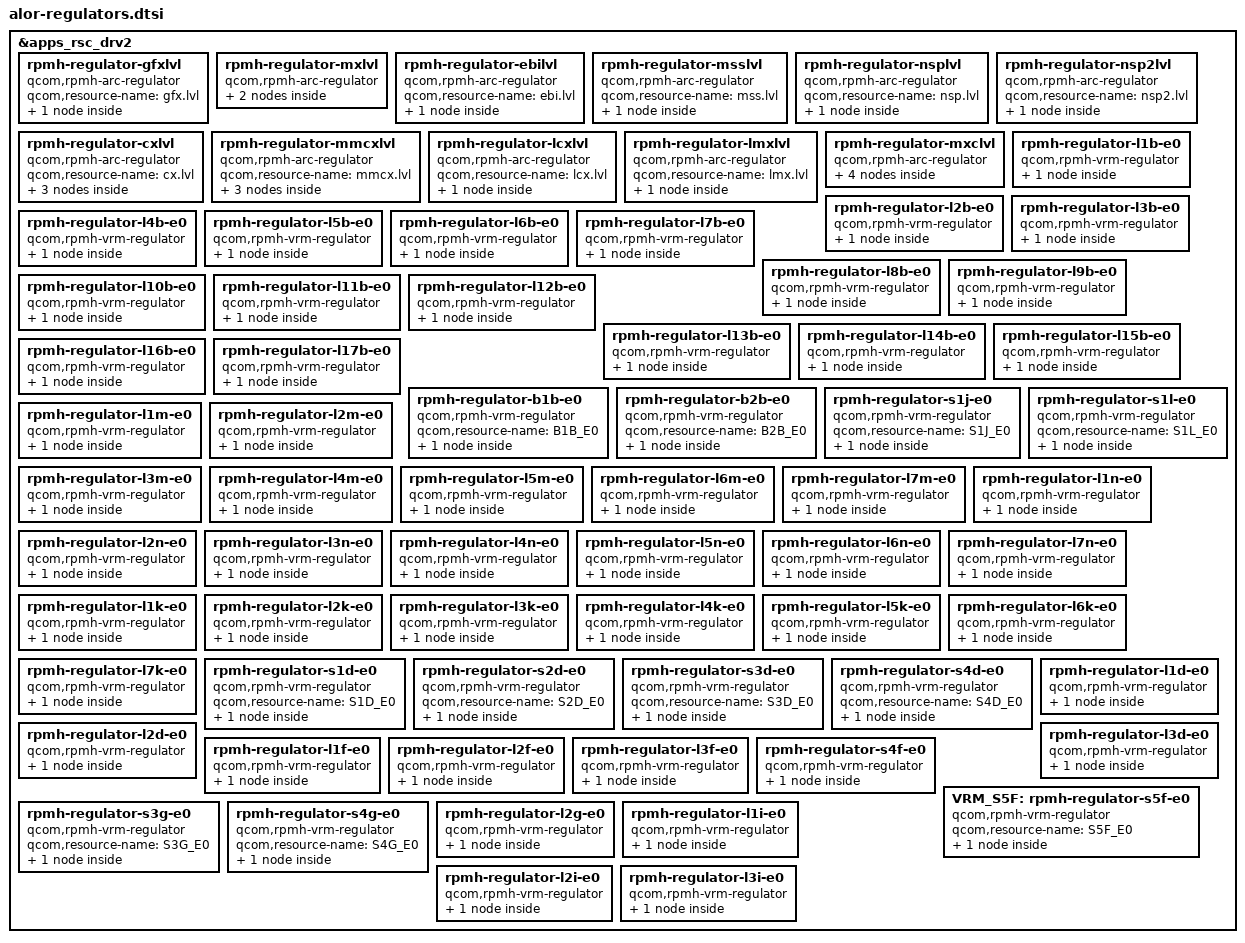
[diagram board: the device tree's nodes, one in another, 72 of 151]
// SPDX-License-Identifier: BSD-3-Clause
/*
 * Copyright (c) Qualcomm Technologies, Inc. and/or its subsidiaries.
 */

#include <dt-bindings/regulator/qcom,rpmh-regulator-levels.h>

&apps_rsc_drv2 {
	rpmh-regulator-gfxlvl {
		compatible = "qcom,rpmh-arc-regulator";
		qcom,resource-name = "gfx.lvl";
		VDD_GFX_LEVEL:
		S6G_LEVEL: S6G_E0_LEVEL:
		pm8550ve_g_s6_level: vreg-pm8550ve-g-s6-level {
			regulator-name = "pm8550ve_g_s6_level";
			qcom,set = <RPMH_REGULATOR_SET_ALL>;
			regulator-min-microvolt =
				<RPMH_REGULATOR_LEVEL_RETENTION>;
			regulator-max-microvolt =
				<RPMH_REGULATOR_LEVEL_MAX>;
			qcom,init-voltage-level =
				<RPMH_REGULATOR_LEVEL_RETENTION>;
		};
	};

	rpmh-regulator-mxlvl {
		compatible = "qcom,rpmh-arc-regulator";
		qcom,resource-name = "mx.lvl";
		proxy-supply = <&VDD_MXA_LEVEL>;
		VDD_MXA_LEVEL: VDD_MX_LEVEL:
		S8F_LEVEL: S8F_E0_LEVEL:
		pm8550ve_f_s8_level: vreg-pm8550ve-f-s8-level {
			regulator-name = "pm8550ve_f_s8_level";
			qcom,set = <RPMH_REGULATOR_SET_ALL>;
			regulator-min-microvolt =
				<RPMH_REGULATOR_LEVEL_RETENTION>;
			regulator-max-microvolt =
				<RPMH_REGULATOR_LEVEL_MAX>;
			qcom,init-voltage-level =
				<RPMH_REGULATOR_LEVEL_TURBO>;
			qcom,proxy-consumer-enable;
			qcom,proxy-consumer-voltage =
				<RPMH_REGULATOR_LEVEL_TURBO
				 RPMH_REGULATOR_LEVEL_MAX>;
		};

		VDD_MXA_LEVEL_AO: VDD_MX_LEVEL_AO:
		S8F_LEVEL_AO: S8F_E0_LEVEL_A0:
		pm8550ve_f_s8_level_ao: vreg-pm8550ve-f-s8-level-ao {
			regulator-name = "pm8550ve_f_s8_level_ao";
			qcom,set = <RPMH_REGULATOR_SET_ACTIVE>;
			regulator-min-microvolt =
				<RPMH_REGULATOR_LEVEL_RETENTION>;
			regulator-max-microvolt =
				<RPMH_REGULATOR_LEVEL_MAX>;
			qcom,init-voltage-level =
				<RPMH_REGULATOR_LEVEL_RETENTION>;
		};
	};

	rpmh-regulator-ebilvl {
		compatible = "qcom,rpmh-arc-regulator";
		qcom,resource-name = "ebi.lvl";
		VDD_EBI_LEVEL:
		S1C_LEVEL: S1C_E0_LEVEL:
		pmg1110_c_s1_level: vreg-pmg1110-c-s1-level {
			regulator-name = "pmg1110_c_s1_level";
			qcom,set = <RPMH_REGULATOR_SET_ALL>;
			regulator-min-microvolt =
				<RPMH_REGULATOR_LEVEL_RETENTION>;
			regulator-max-microvolt =
				<RPMH_REGULATOR_LEVEL_MAX>;
			qcom,init-voltage-level =
				<RPMH_REGULATOR_LEVEL_RETENTION>;
		};
	};

	rpmh-regulator-msslvl {
		compatible = "qcom,rpmh-arc-regulator";
		qcom,resource-name = "mss.lvl";
		VDD_MODEM_LEVEL:
		S5G_LEVEL: S5G_E0_LEVEL:
		pm8550ve_g_s5_level: vreg-pm8550ve-g-s5-level {
			regulator-name = "pm8550ve_g_s5_level";
			qcom,set = <RPMH_REGULATOR_SET_ALL>;
			regulator-min-microvolt =
				<RPMH_REGULATOR_LEVEL_RETENTION>;
			regulator-max-microvolt =
				<RPMH_REGULATOR_LEVEL_MAX>;
			qcom,init-voltage-level =
				<RPMH_REGULATOR_LEVEL_RETENTION>;
		};
	};

	rpmh-regulator-nsplvl {
		compatible = "qcom,rpmh-arc-regulator";
		qcom,resource-name = "nsp.lvl";
		VDD_NSP1_LEVEL:
		S5D_LEVEL: S5D_E0_LEVEL:
		pm8550ve_d_s5_level: vreg-pm8550ve-d-s5-level {
			regulator-name = "pm8550ve_d_s5_level";
			qcom,set = <RPMH_REGULATOR_SET_ALL>;
			regulator-min-microvolt =
				<RPMH_REGULATOR_LEVEL_RETENTION>;
			regulator-max-microvolt =
				<RPMH_REGULATOR_LEVEL_MAX>;
			qcom,init-voltage-level =
				<RPMH_REGULATOR_LEVEL_RETENTION>;
		};
	};

	rpmh-regulator-nsp2lvl {
		compatible = "qcom,rpmh-arc-regulator";
		qcom,resource-name = "nsp2.lvl";
		VDD_NSP2_LEVEL:
		S7D_LEVEL: S7D_E0_LEVEL:
		pm8550ve_d_s7_level: vreg-pm850ve-d-s7-level {
			regulator-name = "pm8550ve_d_s7_level";
			qcom,set = <RPMH_REGULATOR_SET_ALL>;
			regulator-min-microvolt =
				<RPMH_REGULATOR_LEVEL_RETENTION>;
			regulator-max-microvolt =
				<RPMH_REGULATOR_LEVEL_MAX>;
			qcom,init-voltage-level =
				<RPMH_REGULATOR_LEVEL_RETENTION>;
		};
	};

	rpmh-regulator-cxlvl {
		compatible = "qcom,rpmh-arc-regulator";
		qcom,resource-name = "cx.lvl";
		VDD_CX_LEVEL:
		S1F_LEVEL: S1F_E0_LEVEL:
		pm8550ve_f_s1_level: vreg-pm8550ve-f-s1-level {
			regulator-name = "pm8550ve_f_s1_level";
			qcom,set = <RPMH_REGULATOR_SET_ALL>;
			regulator-min-microvolt =
				<RPMH_REGULATOR_LEVEL_RETENTION>;
			regulator-max-microvolt =
				<RPMH_REGULATOR_LEVEL_MAX>;
			qcom,init-voltage-level =
				<RPMH_REGULATOR_LEVEL_TURBO>;
		};

		VDD_CX_LEVEL_AO:
		S1F_LEVEL_AO: S1F_E0_LEVEL_A0:
		pm8550ve_f_s1_level_ao: vreg-pm8550ve0-f-s1-level-ao {
			regulator-name = "pm8550ve_f_s1_level_ao";
			qcom,set = <RPMH_REGULATOR_SET_ACTIVE>;
			regulator-min-microvolt =
				<RPMH_REGULATOR_LEVEL_RETENTION>;
			regulator-max-microvolt =
				<RPMH_REGULATOR_LEVEL_MAX>;
			qcom,init-voltage-level =
				<RPMH_REGULATOR_LEVEL_RETENTION>;
		};

		VDD_CX_MMCX_SUPPLY_LEVEL:
		vreg-pm8550ve-f-s1-mmcx-sup-level {
			regulator-name = "pm8550ve_f_s1_mmcx_sup_level";
			qcom,set = <RPMH_REGULATOR_SET_ALL>;
			regulator-min-microvolt =
				<RPMH_REGULATOR_LEVEL_MIN_SVS>;
			regulator-max-microvolt =
				<RPMH_REGULATOR_LEVEL_MAX>;
			qcom,init-voltage-level =
				<RPMH_REGULATOR_LEVEL_MIN_SVS>;
		};
	};

	rpmh-regulator-mmcxlvl {
		compatible = "qcom,rpmh-arc-regulator";
		qcom,resource-name = "mmcx.lvl";
		VDD_MMCX_LEVEL: VDD_MM_LEVEL:
		S2F_LEVEL: S2F_E0_LEVEL:
		pm8550ve_f_s2_level: vreg-pm8550ve-f-s2-level {
			regulator-name = "pm8550ve_f_s2_level";
			qcom,set = <RPMH_REGULATOR_SET_ALL>;
			pm8550ve_f_s2_level-parent-supply =
				<&VDD_CX_MMCX_SUPPLY_LEVEL>;
			regulator-min-microvolt =
				<RPMH_REGULATOR_LEVEL_LOW_SVS_D1>;
			regulator-max-microvolt =
				<RPMH_REGULATOR_LEVEL_MAX>;
			qcom,init-voltage-level =
				<RPMH_REGULATOR_LEVEL_TURBO>;
		};

		VDD_MMCX_LEVEL_AO: VDD_MM_LEVEL_AO:
		S2F_LEVEL_AO: S2F_E0_LEVEL_A0:
		pm8550ve_f_s2_level_ao: vreg-pm8550ve-f-s2-level-ao {
			regulator-name = "pm8550ve_f_s2_level_ao";
			qcom,set = <RPMH_REGULATOR_SET_ACTIVE>;
			regulator-min-microvolt =
				<RPMH_REGULATOR_LEVEL_LOW_SVS_D1>;
			regulator-max-microvolt =
				<RPMH_REGULATOR_LEVEL_MAX>;
			qcom,init-voltage-level =
				<RPMH_REGULATOR_LEVEL_LOW_SVS_D1>;
		};

		vreg-pm8550ve-f-s2-level-so {
			regulator-name = "pm8550ve_f_s2_level_so";
			qcom,set = <RPMH_REGULATOR_SET_SLEEP>;
			regulator-min-microvolt =
				<RPMH_REGULATOR_LEVEL_LOW_SVS_D1>;
			regulator-max-microvolt =
				<RPMH_REGULATOR_LEVEL_MAX>;
			qcom,init-voltage-level =
				<RPMH_REGULATOR_LEVEL_LOW_SVS_D1>;
		};
	};

	rpmh-regulator-lcxlvl {
		compatible = "qcom,rpmh-arc-regulator";
		qcom,resource-name = "lcx.lvl";
		VDD_LPI_CX_LEVEL:
		L3G_LEVEL: L3G_E0_LEVEL:
		pm8550ve_g_l3_level: vreg-pm8550ve-g-l3-level {
			regulator-name = "pm8550ve_g_l3_level";
			qcom,set = <RPMH_REGULATOR_SET_ALL>;
			regulator-min-microvolt =
				<RPMH_REGULATOR_LEVEL_RETENTION>;
			regulator-max-microvolt =
				<RPMH_REGULATOR_LEVEL_MAX>;
			qcom,init-voltage-level =
				<RPMH_REGULATOR_LEVEL_RETENTION>;
		};
	};

	rpmh-regulator-lmxlvl {
		compatible = "qcom,rpmh-arc-regulator";
		qcom,resource-name = "lmx.lvl";
		VDD_LPI_MX_LEVEL:
		L1G_LEVEL: L1G_E0_LEVEL:
		pm8550ve_g_l1_level: vreg-pm8550ve-g-l1-level {
			regulator-name = "pm8550ve_g_l1_level";
			qcom,set = <RPMH_REGULATOR_SET_ALL>;
			regulator-min-microvolt =
				<RPMH_REGULATOR_LEVEL_RETENTION>;
			regulator-max-microvolt =
				<RPMH_REGULATOR_LEVEL_MAX>;
			qcom,init-voltage-level =
				<RPMH_REGULATOR_LEVEL_RETENTION>;
		};
	};

	rpmh-regulator-mxclvl {
		compatible = "qcom,rpmh-arc-regulator";
		qcom,resource-name = "mxc.lvl";
		proxy-supply = <&VDD_MXC_LEVEL>;
		VDD_MXC_LEVEL:
		S1G_LEVEL: S1G_E0_LEVEL:
		pm8550ve_g_s1_level: vreg-pm8550ve-g-s1-level {
			regulator-name = "pm8550ve_g_s1_level";
			qcom,set = <RPMH_REGULATOR_SET_ALL>;
			regulator-min-microvolt =
				<RPMH_REGULATOR_LEVEL_RETENTION>;
			regulator-max-microvolt =
				<RPMH_REGULATOR_LEVEL_MAX>;
			qcom,init-voltage-level =
				<RPMH_REGULATOR_LEVEL_TURBO>;
			qcom,proxy-consumer-enable;
			qcom,proxy-consumer-voltage =
				<RPMH_REGULATOR_LEVEL_TURBO
				 RPMH_REGULATOR_LEVEL_MAX>;
		};

		VDD_MXC_LEVEL_AO:
		S1G_LEVEL_AO: S1G_E0_LEVEL_A0:
		pm8550ve_g_s1_level_ao: vreg-pm8550ve-g-s1-level-ao {
			regulator-name = "pm8550ve_g_s1_level_ao";
			qcom,set = <RPMH_REGULATOR_SET_ACTIVE>;
			regulator-min-microvolt =
				<RPMH_REGULATOR_LEVEL_RETENTION>;
			regulator-max-microvolt =
				<RPMH_REGULATOR_LEVEL_MAX>;
			qcom,init-voltage-level =
				<RPMH_REGULATOR_LEVEL_RETENTION>;
		};

		VDD_MXC_MMCX_VOTER_LEVEL: VDD_MXC_MM_VOTER_LEVEL:
		VDD_MM_MXC_VOTER_LEVEL: vreg-pm8550ve-g-s1-mmcx-voter-level {
			regulator-name = "pm8550ve_g_s1_mmcx_voter_level";
			pm8550ve_g_s1_mmcx_voter_level-parent-supply =
				<&VDD_MMCX_LEVEL>;
			qcom,set = <RPMH_REGULATOR_SET_ALL>;
			regulator-min-microvolt =
				<RPMH_REGULATOR_LEVEL_MIN_SVS>;
			regulator-max-microvolt =
				<RPMH_REGULATOR_LEVEL_MAX>;
			qcom,init-voltage-level =
				<RPMH_REGULATOR_LEVEL_MIN_SVS>;
		};

		VDD_MXC_GFX_VOTER_LEVEL: VDD_GFX_MXC_VOTER_LEVEL:
			vreg-pm8550ve-g-s1-gfx-voter-level {
			regulator-name = "pm8550ve_g_s1_gfx_voter_level";
			pm8550ve_g_s1_gfx_voter_level-parent-supply =
				<&VDD_GFX_LEVEL>;
			qcom,set = <RPMH_REGULATOR_SET_ALL>;
			regulator-min-microvolt =
				<RPMH_REGULATOR_LEVEL_MIN_SVS>;
			regulator-max-microvolt =
				<RPMH_REGULATOR_LEVEL_MAX>;
			qcom,init-voltage-level =
				<RPMH_REGULATOR_LEVEL_MIN_SVS>;
		};
	};

	rpmh-regulator-l1b-e0 {
		compatible = "qcom,rpmh-vrm-regulator";
		qcom,resource-name = "L1B_E0";
		qcom,regulator-type = "pmic5-ldo";
		qcom,supported-modes =
			<RPMH_REGULATOR_MODE_LPM
			 RPMH_REGULATOR_MODE_HPM>;
		qcom,mode-threshold-currents = <0 30000>;

		L1B: L1B_E0: pm_humu_l1: vreg-pm-humu-l1 {
			regulator-name = "pm_humu_l1";
			qcom,set = <RPMH_REGULATOR_SET_ALL>;
			regulator-min-microvolt = <1080000>;
			regulator-max-microvolt = <2000000>;
			qcom,init-voltage = <1080000>;
			qcom,init-mode = <RPMH_REGULATOR_MODE_HPM>;
		};
	};

	rpmh-regulator-l2b-e0 {
		compatible = "qcom,rpmh-vrm-regulator";
		qcom,resource-name = "L2B_E0";
		qcom,regulator-type = "pmic5-ldo";
		qcom,supported-modes =
			<RPMH_REGULATOR_MODE_LPM
			 RPMH_REGULATOR_MODE_HPM>;
		qcom,mode-threshold-currents = <0 10000>;

		L2B: L2B_E0: pm_humu_l2: vreg-pm-humu-l2 {
			regulator-name = "pm_humu_l2";
			qcom,set = <RPMH_REGULATOR_SET_ALL>;
			regulator-min-microvolt = <2600000>;
			regulator-max-microvolt = <3544000>;
			qcom,init-voltage = <2600000>;
			qcom,init-mode = <RPMH_REGULATOR_MODE_HPM>;
		};
	};

	rpmh-regulator-l3b-e0 {
		compatible = "qcom,rpmh-vrm-regulator";
		qcom,resource-name = "L3B_E0";
		qcom,regulator-type = "pmic5-ldo";
		qcom,supported-modes =
			<RPMH_REGULATOR_MODE_LPM
			 RPMH_REGULATOR_MODE_HPM>;
		qcom,mode-threshold-currents = <0 10000>;

		L3B: L3B_E0: pm_humu_l3: vreg-pm-humu-l3 {
			regulator-name = "pm_humu_l3";
			qcom,set = <RPMH_REGULATOR_SET_ALL>;
			regulator-min-microvolt = <1170000>;
			regulator-max-microvolt = <1370000>;
			qcom,init-voltage = <1200000>;
			qcom,init-mode = <RPMH_REGULATOR_MODE_HPM>;
		};
	};

	rpmh-regulator-l4b-e0 {
		compatible = "qcom,rpmh-vrm-regulator";
		qcom,resource-name = "L4B_E0";
		qcom,regulator-type = "pmic5-ldo";
		qcom,supported-modes =
			<RPMH_REGULATOR_MODE_LPM
			 RPMH_REGULATOR_MODE_HPM>;
		qcom,mode-threshold-currents = <0 30000>;

		L4B: L4B_E0: pm_humu_l4: vreg-pm-humu-l4 {
			regulator-name = "pm_humu_l4";
			qcom,set = <RPMH_REGULATOR_SET_ALL>;
			regulator-min-microvolt = <1650000>;
			regulator-max-microvolt = <1950000>;
			qcom,init-voltage = <1650000>;
			qcom,init-mode = <RPMH_REGULATOR_MODE_HPM>;
		};
	};

	rpmh-regulator-l5b-e0 {
		compatible = "qcom,rpmh-vrm-regulator";
		qcom,resource-name = "L5B_E0";
		qcom,regulator-type = "pmic5-ldo";
		qcom,supported-modes =
			<RPMH_REGULATOR_MODE_LPM
			 RPMH_REGULATOR_MODE_HPM>;
		qcom,mode-threshold-currents = <0 10000>;

		L5B: L5B_E0: pm_humu_l5: vreg-pm-humu-l5 {
			regulator-name = "pm_humu_l5";
			qcom,set = <RPMH_REGULATOR_SET_ALL>;
			regulator-min-microvolt = <2700000>;
			regulator-max-microvolt = <3554000>;
			qcom,init-voltage = <3104000>;
			qcom,init-mode = <RPMH_REGULATOR_MODE_HPM>;
		};
	};

	rpmh-regulator-l6b-e0 {
		compatible = "qcom,rpmh-vrm-regulator";
		qcom,resource-name = "L6B_E0";
		qcom,regulator-type = "pmic5-ldo";
		qcom,supported-modes =
			<RPMH_REGULATOR_MODE_LPM
			 RPMH_REGULATOR_MODE_HPM>;
		qcom,mode-threshold-currents = <0 10000>;

		L6B: L6B_E0: pm_humu_l6: vreg-pm-humu-l6 {
			regulator-name = "pm_humu_l6";
			qcom,set = <RPMH_REGULATOR_SET_ALL>;
			regulator-min-microvolt = <1504000>;
			regulator-max-microvolt = <3544000>;
			qcom,init-voltage = <1504000>;
			qcom,init-mode = <RPMH_REGULATOR_MODE_HPM>;
		};
	};

	rpmh-regulator-l7b-e0 {
		compatible = "qcom,rpmh-vrm-regulator";
		qcom,resource-name = "L7B_E0";
		qcom,regulator-type = "pmic5-ldo";
		qcom,supported-modes =
			<RPMH_REGULATOR_MODE_LPM
			 RPMH_REGULATOR_MODE_HPM>;
		qcom,mode-threshold-currents = <0 10000>;

		L7B: L7B_E0: pm_humu_l7: vreg-pm-humu-l7 {
			regulator-name = "pm_humu_l7";
			qcom,set = <RPMH_REGULATOR_SET_ALL>;
			regulator-min-microvolt = <1504000>;
			regulator-max-microvolt = <3544000>;
			qcom,init-voltage = <1504000>;
			qcom,init-mode = <RPMH_REGULATOR_MODE_HPM>;
		};
	};

	rpmh-regulator-l8b-e0 {
		compatible = "qcom,rpmh-vrm-regulator";
		qcom,resource-name = "L8B_E0";
		qcom,regulator-type = "pmic5-ldo";
		qcom,supported-modes =
			<RPMH_REGULATOR_MODE_LPM
			 RPMH_REGULATOR_MODE_HPM>;
		qcom,mode-threshold-currents = <0 10000>;

		L8B: L8B_E0: pm_humu_l8: vreg-pm-humu-l8 {
			regulator-name = "pm_humu_l8";
			qcom,set = <RPMH_REGULATOR_SET_ALL>;
			regulator-min-microvolt = <1650000>;
			regulator-max-microvolt = <3544000>;
			qcom,init-voltage = <1650000>;
			qcom,init-mode = <RPMH_REGULATOR_MODE_HPM>;
		};
	};

	rpmh-regulator-l9b-e0 {
		compatible = "qcom,rpmh-vrm-regulator";
		qcom,resource-name = "L9B_E0";
		qcom,regulator-type = "pmic5-ldo";
		qcom,supported-modes =
			<RPMH_REGULATOR_MODE_LPM
			 RPMH_REGULATOR_MODE_HPM>;
		qcom,mode-threshold-currents = <0 10000>;

		L9B: L9B_E0: pm_humu_l9: vreg-pm-humu-l9 {
			regulator-name = "pm_humu_l9";
			qcom,set = <RPMH_REGULATOR_SET_ALL>;
			regulator-min-microvolt = <2700000>;
			regulator-max-microvolt = <3300000>;
			qcom,init-voltage = <2700000>;
			qcom,init-mode = <RPMH_REGULATOR_MODE_HPM>;
		};
	};

	rpmh-regulator-l10b-e0 {
		compatible = "qcom,rpmh-vrm-regulator";
		qcom,resource-name = "L10B_E0";
		qcom,regulator-type = "pmic5-ldo";
		qcom,supported-modes =
			<RPMH_REGULATOR_MODE_LPM
			 RPMH_REGULATOR_MODE_HPM>;
		qcom,mode-threshold-currents = <0 30000>;
		proxy-supply = <&L10B>;

		L10B: L10B_E0: pm_humu_l10: vreg-pm-humu-l10 {
			regulator-name = "pm_humu_l10";
			qcom,set = <RPMH_REGULATOR_SET_ALL>;
			regulator-min-microvolt = <1650000>;
			regulator-max-microvolt = <1950000>;
			qcom,init-voltage = <1650000>;
			qcom,init-mode = <RPMH_REGULATOR_MODE_HPM>;
			qcom,proxy-consumer-enable;
			qcom,proxy-consumer-current = <154000>;
		};
	};

	rpmh-regulator-l11b-e0 {
		compatible = "qcom,rpmh-vrm-regulator";
		qcom,resource-name = "L11B_E0";
		qcom,regulator-type = "pmic5-ldo";
		qcom,supported-modes =
			<RPMH_REGULATOR_MODE_LPM
			 RPMH_REGULATOR_MODE_HPM>;
		qcom,mode-threshold-currents = <0 30000>;
		proxy-supply = <&L11B>;

		L11B: L11B_E0: pm_humu_l11: vreg-pm-humu-l11 {
			regulator-name = "pm_humu_l11";
			qcom,set = <RPMH_REGULATOR_SET_ALL>;
			regulator-min-microvolt = <1030000>;
			regulator-max-microvolt = <1100000>;
			qcom,init-voltage = <1030000>;
			qcom,init-mode = <RPMH_REGULATOR_MODE_HPM>;
			qcom,proxy-consumer-enable;
			qcom,proxy-consumer-current = <220000>;
		};
	};

	rpmh-regulator-l12b-e0 {
		compatible = "qcom,rpmh-vrm-regulator";
		qcom,resource-name = "L12B_E0";
		qcom,regulator-type = "pmic5-ldo";
		qcom,supported-modes =
			<RPMH_REGULATOR_MODE_LPM
			 RPMH_REGULATOR_MODE_HPM>;
		qcom,mode-threshold-currents = <0 30000>;

		L12B: L12B_E0: pm_humu_l12: vreg-pm-humu-l12 {
			regulator-name = "pm_humu_l12";
			qcom,set = <RPMH_REGULATOR_SET_ALL>;
			regulator-min-microvolt = <1080000>;
			regulator-max-microvolt = <1320000>;
			qcom,init-voltage = <1080000>;
			qcom,init-mode = <RPMH_REGULATOR_MODE_HPM>;
		};
	};

	rpmh-regulator-l13b-e0 {
		compatible = "qcom,rpmh-vrm-regulator";
		qcom,resource-name = "L13B_E0";
		qcom,regulator-type = "pmic5-ldo";
		qcom,supported-modes =
			<RPMH_REGULATOR_MODE_LPM
			 RPMH_REGULATOR_MODE_HPM>;
		qcom,mode-threshold-currents = <0 10000>;
		proxy-supply = <&L13B>;

		L13B: L13B_E0: pm_humu_l13: vreg-pm-humu-l13 {
			regulator-name = "pm_humu_l13";
			qcom,set = <RPMH_REGULATOR_SET_ALL>;
			regulator-min-microvolt = <2650000>;
			regulator-max-microvolt = <3544000>;
			qcom,init-voltage = <2650000>;
			qcom,init-mode = <RPMH_REGULATOR_MODE_HPM>;
			qcom,proxy-consumer-enable;
			qcom,proxy-consumer-current = <10000>;
		};
	};

	rpmh-regulator-l14b-e0 {
		compatible = "qcom,rpmh-vrm-regulator";
		qcom,resource-name = "L14B_E0";
		qcom,regulator-type = "pmic5-ldo";
		qcom,supported-modes =
			<RPMH_REGULATOR_MODE_LPM
			 RPMH_REGULATOR_MODE_HPM>;
		qcom,mode-threshold-currents = <0 10000>;

		L14B: L14B_E0: pm_humu_l14: vreg-pm-humu-l14 {
			regulator-name = "pm_humu_l14";
			qcom,set = <RPMH_REGULATOR_SET_ALL>;
			regulator-min-microvolt = <2700000>;
			regulator-max-microvolt = <3544000>;
			qcom,init-voltage = <2700000>;
			qcom,init-mode = <RPMH_REGULATOR_MODE_HPM>;
		};
	};

	rpmh-regulator-l15b-e0 {
		compatible = "qcom,rpmh-vrm-regulator";
		qcom,resource-name = "L15B_E0";
		qcom,regulator-type = "pmic5-ldo";
		qcom,supported-modes =
			<RPMH_REGULATOR_MODE_LPM
			 RPMH_REGULATOR_MODE_HPM>;
		qcom,mode-threshold-currents = <0 30000>;

		L15B: L15B_E0: pm_humu_l15: vreg-pm-humu-l15 {
			regulator-name = "pm_humu_l15";
			qcom,set = <RPMH_REGULATOR_SET_ALL>;
			regulator-min-microvolt = <1620000>;
			regulator-max-microvolt = <2000000>;
			qcom,init-voltage = <1800000>;
			qcom,init-mode = <RPMH_REGULATOR_MODE_HPM>;
		};
	};

	rpmh-regulator-l16b-e0 {
		compatible = "qcom,rpmh-vrm-regulator";
		qcom,resource-name = "L16B_E0";
		qcom,regulator-type = "pmic5-ldo";
		qcom,supported-modes =
			<RPMH_REGULATOR_MODE_LPM
			 RPMH_REGULATOR_MODE_HPM>;
		qcom,mode-threshold-currents = <0 10000>;

		L16B: L16B_E0: pm_humu_l16: vreg-pm-humu-l16 {
			regulator-name = "pm_humu_l16";
			qcom,set = <RPMH_REGULATOR_SET_ALL>;
			regulator-min-microvolt = <1600000>;
			regulator-max-microvolt = <3544000>;
			qcom,init-voltage = <1600000>;
			qcom,init-mode = <RPMH_REGULATOR_MODE_HPM>;
		};
	};

	rpmh-regulator-l17b-e0 {
		compatible = "qcom,rpmh-vrm-regulator";
		qcom,resource-name = "L17B_E0";
		qcom,regulator-type = "pmic5-ldo";
		qcom,supported-modes =
			<RPMH_REGULATOR_MODE_LPM
			 RPMH_REGULATOR_MODE_HPM>;
		qcom,mode-threshold-currents = <0 10000>;

		L17B: L17B_E0: pm_humu_l17: vreg-pm-humu-l17 {
			regulator-name = "pm_humu_l17";
			qcom,set = <RPMH_REGULATOR_SET_ALL>;
			regulator-min-microvolt = <2504000>;
			regulator-max-microvolt = <2504000>;
			qcom,init-voltage = <2504000>;
			qcom,init-mode = <RPMH_REGULATOR_MODE_HPM>;
		};
	};

	rpmh-regulator-b1b-e0 {
		compatible = "qcom,rpmh-vrm-regulator";
		qcom,resource-name = "B1B_E0";

		BOB1: BOB1_E0: pm_humu_bob1: vreg-pm-humu-bob1 {
			regulator-name = "pm_humu_bob1";
			qcom,set = <RPMH_REGULATOR_SET_ALL>;
			regulator-min-microvolt = <2500000>;
			regulator-max-microvolt = <4500000>;
			qcom,init-voltage = <3296000>;
		};
	};

	rpmh-regulator-b2b-e0 {
		compatible = "qcom,rpmh-vrm-regulator";
		qcom,resource-name = "B2B_E0";

		BOB2: BOB2_E0: pm_humu_bob2: vreg-pm-humu-bob2 {
			regulator-name = "pm_humu_bob2";
			qcom,set = <RPMH_REGULATOR_SET_ALL>;
			regulator-min-microvolt = <2500000>;
			regulator-max-microvolt = <4500000>;
			qcom,init-voltage = <2720000>;
		};
	};

	rpmh-regulator-s1j-e0 {
		compatible = "qcom,rpmh-vrm-regulator";
		qcom,resource-name = "S1J_E0";

		S1J: S1J_E0: pmg1110_j_s1: vreg-pmg1110-j-s1 {
			regulator-name = "pmg1110_j_s1";
			qcom,set = <RPMH_REGULATOR_SET_ALL>;
			regulator-min-microvolt = <556000>;
			regulator-max-microvolt = <816000>;
			qcom,init-voltage = <556000>;
		};
	};

	rpmh-regulator-s1l-e0 {
		compatible = "qcom,rpmh-vrm-regulator";
		qcom,resource-name = "S1L_E0";

		S1L: S1L_E0: pmg1110_l_s1: vreg-pmg1110-l-s1 {
			regulator-name = "pmg1110_l_s1";
			qcom,set = <RPMH_REGULATOR_SET_ALL>;
			regulator-min-microvolt = <700000>;
			regulator-max-microvolt = <1352000>;
			qcom,init-voltage = <700000>;
		};
	};

	rpmh-regulator-l1m-e0 {
		compatible = "qcom,rpmh-vrm-regulator";
		qcom,resource-name = "L1M_E0";
		qcom,regulator-type = "pmic5-ldo";
		qcom,supported-modes =
			<RPMH_REGULATOR_MODE_LPM
			RPMH_REGULATOR_MODE_HPM>;
		qcom,mode-threshold-currents = <0 30000>;

		L1M: L1M_E0: pm8010_m_l1: vreg-pm8010-m-l1 {
			regulator-name = "pm8010_m_l1";
			qcom,set = <RPMH_REGULATOR_SET_ALL>;
			regulator-min-microvolt = <900000>;
			regulator-max-microvolt = <1100000>;
			qcom,init-voltage = <900000>;
			qcom,init-mode = <RPMH_REGULATOR_MODE_HPM>;
		};
	};

	rpmh-regulator-l2m-e0 {
		compatible = "qcom,rpmh-vrm-regulator";
		qcom,resource-name = "L2M_E0";
		qcom,regulator-type = "pmic5-ldo";
		qcom,supported-modes =
			<RPMH_REGULATOR_MODE_LPM
			RPMH_REGULATOR_MODE_HPM>;
		qcom,mode-threshold-currents = <0 30000>;

		L2M: L2M_E0: pm8010_m_l2: vreg-pm8010-m-l2 {
			regulator-name = "pm8010_m_l2";
			qcom,set = <RPMH_REGULATOR_SET_ALL>;
			regulator-min-microvolt = <1000000>;
			regulator-max-microvolt = <1200000>;
			qcom,init-voltage = <1000000>;
			qcom,init-mode = <RPMH_REGULATOR_MODE_HPM>;
		};
	};

	rpmh-regulator-l3m-e0 {
		compatible = "qcom,rpmh-vrm-regulator";
		qcom,resource-name = "L3M_E0";
		qcom,regulator-type = "pmic5-ldo";
		qcom,supported-modes =
			<RPMH_REGULATOR_MODE_LPM
			RPMH_REGULATOR_MODE_HPM>;
		qcom,mode-threshold-currents = <0 10000>;

		L3M: L3M_E0: pm8010_m_l3: vreg-pm8010-m-l3 {
			regulator-name = "pm8010_m_l3";
			qcom,set = <RPMH_REGULATOR_SET_ALL>;
			regulator-min-microvolt = <2700000>;
			regulator-max-microvolt = <2900000>;
			qcom,init-voltage = <2700000>;
			qcom,init-mode = <RPMH_REGULATOR_MODE_HPM>;
		};
	};

	rpmh-regulator-l4m-e0 {
		compatible = "qcom,rpmh-vrm-regulator";
		qcom,resource-name = "L4M_E0";
		qcom,regulator-type = "pmic5-ldo";
		qcom,supported-modes =
			<RPMH_REGULATOR_MODE_LPM
			RPMH_REGULATOR_MODE_HPM>;
		qcom,mode-threshold-currents = <0 10000>;

		L4M: L4M_E0: pm8010_m_l4: vreg-pm8010-m-l4 {
			regulator-name = "pm8010_m_l4";
			qcom,set = <RPMH_REGULATOR_SET_ALL>;
			regulator-min-microvolt = <2100000>;
			regulator-max-microvolt = <2300000>;
			qcom,init-voltage = <2100000>;
			qcom,init-mode = <RPMH_REGULATOR_MODE_HPM>;
		};
	};

	rpmh-regulator-l5m-e0 {
		compatible = "qcom,rpmh-vrm-regulator";
		qcom,resource-name = "L5M_E0";
		qcom,regulator-type = "pmic5-ldo";
		qcom,supported-modes =
			<RPMH_REGULATOR_MODE_LPM
			RPMH_REGULATOR_MODE_HPM>;
		qcom,mode-threshold-currents = <0 10000>;

		L5M: L5M_E0: pm8010_m_l5: vreg-pm8010-m-l5 {
			regulator-name = "pm8010_m_l5";
			qcom,set = <RPMH_REGULATOR_SET_ALL>;
			regulator-min-microvolt = <1504000>;
			regulator-max-microvolt = <3544000>;
			qcom,init-voltage = <1504000>;
			qcom,init-mode = <RPMH_REGULATOR_MODE_HPM>;
		};
	};

	rpmh-regulator-l6m-e0 {
		compatible = "qcom,rpmh-vrm-regulator";
		qcom,resource-name = "L6M_E0";
		qcom,regulator-type = "pmic5-ldo";
		qcom,supported-modes =
			<RPMH_REGULATOR_MODE_LPM
			RPMH_REGULATOR_MODE_HPM>;
		qcom,mode-threshold-currents = <0 10000>;

		L6M: L6M_E0: pm8010_m_l6: vreg-pm8010-m-l6 {
			regulator-name = "pm8010_m_l6";
			qcom,set = <RPMH_REGULATOR_SET_ALL>;
			regulator-min-microvolt = <2700000>;
			regulator-max-microvolt = <2900000>;
			qcom,init-voltage = <2700000>;
			qcom,init-mode = <RPMH_REGULATOR_MODE_HPM>;
		};
	};

	rpmh-regulator-l7m-e0 {
		compatible = "qcom,rpmh-vrm-regulator";
		qcom,resource-name = "L7M_E0";
		qcom,regulator-type = "pmic5-ldo";
		qcom,supported-modes =
			<RPMH_REGULATOR_MODE_LPM
			RPMH_REGULATOR_MODE_HPM>;
		qcom,mode-threshold-currents = <0 10000>;

		L7M: L7M_E0: pm8010_m_l7: reg-pm8010-m-l7 {
			regulator-name = "pm8010_m_l7";
			qcom,set = <RPMH_REGULATOR_SET_ALL>;
			regulator-min-microvolt = <2700000>;
			regulator-max-microvolt = <3000000>;
			qcom,init-voltage = <2700000>;
			qcom,init-mode = <RPMH_REGULATOR_MODE_HPM>;
		};
	};

	rpmh-regulator-l1n-e0 {
		compatible = "qcom,rpmh-vrm-regulator";
		qcom,resource-name = "L1N_E0";
		qcom,regulator-type = "pmic5-ldo";
		qcom,supported-modes =
			<RPMH_REGULATOR_MODE_LPM
			RPMH_REGULATOR_MODE_HPM>;
		qcom,mode-threshold-currents = <0 30000>;

		L1N: L1N_E0: pm8010_n_l1: vreg-pm8010-n-l1 {
			regulator-name = "pm8010_n_l1";
			qcom,set = <RPMH_REGULATOR_SET_ALL>;
			regulator-min-microvolt = <1050000>;
			regulator-max-microvolt = <1150000>;
			qcom,init-voltage = <1050000>;
			qcom,init-mode = <RPMH_REGULATOR_MODE_HPM>;
		};
	};

	rpmh-regulator-l2n-e0 {
		compatible = "qcom,rpmh-vrm-regulator";
		qcom,resource-name = "L2N_E0";
		qcom,regulator-type = "pmic5-ldo";
		qcom,supported-modes =
			<RPMH_REGULATOR_MODE_LPM
			RPMH_REGULATOR_MODE_HPM>;
		qcom,mode-threshold-currents = <0 30000>;

		L2N: L2N_E0: pm8010_n_l2: vreg-pm8010-n-l2 {
			regulator-name = "pm8010_n_l2";
			qcom,set = <RPMH_REGULATOR_SET_ALL>;
			regulator-min-microvolt = <1050000>;
			regulator-max-microvolt = <1200000>;
			qcom,init-voltage = <1050000>;
			qcom,init-mode = <RPMH_REGULATOR_MODE_HPM>;
		};
	};

	rpmh-regulator-l3n-e0 {
		compatible = "qcom,rpmh-vrm-regulator";
		qcom,resource-name = "L3N_E0";
		qcom,regulator-type = "pmic5-ldo";
		qcom,supported-modes =
			<RPMH_REGULATOR_MODE_LPM
			RPMH_REGULATOR_MODE_HPM>;
		qcom,mode-threshold-currents = <0 10000>;

		L3N: L3N_E0: pm8010_n_l3: vreg-pm8010-n-l3 {
			regulator-name = "pm8010_n_l3";
			qcom,set = <RPMH_REGULATOR_SET_ALL>;
			regulator-min-microvolt = <1792000>;
			regulator-max-microvolt = <1900000>;
			qcom,init-voltage = <1792000>;
			qcom,init-mode = <RPMH_REGULATOR_MODE_HPM>;
		};
	};

	rpmh-regulator-l4n-e0 {
		compatible = "qcom,rpmh-vrm-regulator";
		qcom,resource-name = "L4N_E0";
		qcom,regulator-type = "pmic5-ldo";
		qcom,supported-modes =
			<RPMH_REGULATOR_MODE_LPM
			RPMH_REGULATOR_MODE_HPM>;
		qcom,mode-threshold-currents = <0 10000>;

		L4N: L4N_E0: pm8010_n_l4: vreg-pm8010-n-l4 {
			regulator-name = "pm8010_n_l4";
			qcom,set = <RPMH_REGULATOR_SET_ALL>;
			regulator-min-microvolt = <1792000>;
			regulator-max-microvolt = <1980000>;
			qcom,init-voltage = <1792000>;
			qcom,init-mode = <RPMH_REGULATOR_MODE_HPM>;
		};
	};

	rpmh-regulator-l5n-e0 {
		compatible = "qcom,rpmh-vrm-regulator";
		qcom,resource-name = "L5N_E0";
		qcom,regulator-type = "pmic5-ldo";
		qcom,supported-modes =
			<RPMH_REGULATOR_MODE_LPM
			RPMH_REGULATOR_MODE_HPM>;
		qcom,mode-threshold-currents = <0 10000>;

		L5N: L5N_E0: pm8010_n_l5: regulator-pm8010-n-l5 {
			regulator-name = "pm8010_n_l5";
			qcom,set = <RPMH_REGULATOR_SET_ALL>;
			regulator-min-microvolt = <1504000>;
			regulator-max-microvolt = <3544000>;
			qcom,init-voltage = <1504000>;
			qcom,init-mode = <RPMH_REGULATOR_MODE_HPM>;
		};
	};

	rpmh-regulator-l6n-e0 {
		compatible = "qcom,rpmh-vrm-regulator";
		qcom,resource-name = "L6N_E0";
		qcom,regulator-type = "pmic5-ldo";
		qcom,supported-modes =
			<RPMH_REGULATOR_MODE_LPM
			RPMH_REGULATOR_MODE_HPM>;
		qcom,mode-threshold-currents = <0 10000>;

		L6N: L6N_E0: pm8010_n_l6: regulator-pm8010-n-l6 {
			regulator-name = "pm8010_n_l6";
			qcom,set = <RPMH_REGULATOR_SET_ALL>;
			regulator-min-microvolt = <2700000>;
			regulator-max-microvolt = <2900000>;
			qcom,init-voltage = <2700000>;
			qcom,init-mode = <RPMH_REGULATOR_MODE_HPM>;
		};
	};

	rpmh-regulator-l7n-e0 {
		compatible = "qcom,rpmh-vrm-regulator";
		qcom,resource-name = "L7N_E0";
		qcom,regulator-type = "pmic5-ldo";
		qcom,supported-modes =
			<RPMH_REGULATOR_MODE_LPM
			RPMH_REGULATOR_MODE_HPM>;
		qcom,mode-threshold-currents = <0 10000>;

		L7N: L7N_E0: pm8010_n_l7: regulator-pm8010-n-l7 {
			regulator-name = "pm8010_n_l7";
			qcom,set = <RPMH_REGULATOR_SET_ALL>;
			regulator-min-microvolt = <3130000>;
			regulator-max-microvolt = <3470000>;
			qcom,init-voltage = <3130000>;
			qcom,init-mode = <RPMH_REGULATOR_MODE_HPM>;
		};
	};

	rpmh-regulator-l1k-e0 {
		compatible = "qcom,rpmh-vrm-regulator";
		qcom,resource-name = "L1K_E0";
		qcom,regulator-type = "pmic5-ldo";
		qcom,supported-modes =
			<RPMH_REGULATOR_MODE_LPM
			 RPMH_REGULATOR_MODE_HPM>;
		qcom,mode-threshold-currents = <0 30000>;

		L1K: L1K_E0: pmr735_d_l1: vreg-pmr735-d-l1 {
			regulator-name = "pmr735_d_l1";
			qcom,set = <RPMH_REGULATOR_SET_ALL>;
			regulator-min-microvolt = <806000>;
			regulator-max-microvolt = <901000>;
			qcom,init-voltage = <806000>;
			qcom,init-mode = <RPMH_REGULATOR_MODE_HPM>;
		};
	};

	rpmh-regulator-l2k-e0 {
		compatible = "qcom,rpmh-vrm-regulator";
		qcom,resource-name = "L2K_E0";
		qcom,regulator-type = "pmic5-ldo";
		qcom,supported-modes =
			<RPMH_REGULATOR_MODE_LPM
			 RPMH_REGULATOR_MODE_HPM>;
		qcom,mode-threshold-currents = <0 30000>;

		L2K: L2K_E0: pmr735_d_l2: vreg-pmr735-d-l2 {
			regulator-name = "pmr735_d_l2";
			qcom,set = <RPMH_REGULATOR_SET_ALL>;
			regulator-min-microvolt = <866000>;
			regulator-max-microvolt = <931000>;
			qcom,init-voltage = <866000>;
			qcom,init-mode = <RPMH_REGULATOR_MODE_HPM>;
		};
	};

	rpmh-regulator-l3k-e0 {
		compatible = "qcom,rpmh-vrm-regulator";
		qcom,resource-name = "L3K_E0";
		qcom,regulator-type = "pmic5-ldo";
		qcom,supported-modes =
			<RPMH_REGULATOR_MODE_LPM
			 RPMH_REGULATOR_MODE_HPM>;
		qcom,mode-threshold-currents = <0 30000>;

		L3K: L3K_E0: pmr735_d_l3: vreg-pmr735-d-l3 {
			regulator-name = "pmr735_d_l3";
			qcom,set = <RPMH_REGULATOR_SET_ALL>;
			regulator-min-microvolt = <1050000>;
			regulator-max-microvolt = <1200000>;
			qcom,init-voltage = <1200000>;
			qcom,init-mode = <RPMH_REGULATOR_MODE_HPM>;
		};
	};

	rpmh-regulator-l4k-e0 {
		compatible = "qcom,rpmh-vrm-regulator";
		qcom,resource-name = "L4K_E0";
		qcom,regulator-type = "pmic5-ldo";
		qcom,supported-modes =
			<RPMH_REGULATOR_MODE_LPM
			 RPMH_REGULATOR_MODE_HPM>;
		qcom,mode-threshold-currents = <0 30000>;

		L4K: L4K_E0: pmr735_d_l4: vreg-pmr735-d-l4 {
			regulator-name = "pmr735_d_l4";
			qcom,set = <RPMH_REGULATOR_SET_ALL>;
			regulator-min-microvolt = <1080000>;
			regulator-max-microvolt = <1256000>;
			qcom,init-voltage = <1080000>;
			qcom,init-mode = <RPMH_REGULATOR_MODE_HPM>;
		};
	};

	rpmh-regulator-l5k-e0 {
		compatible = "qcom,rpmh-vrm-regulator";
		qcom,resource-name = "L5K_E0";
		qcom,regulator-type = "pmic5-ldo";
		qcom,supported-modes =
			<RPMH_REGULATOR_MODE_LPM
			 RPMH_REGULATOR_MODE_HPM>;
		qcom,mode-threshold-currents = <0 30000>;

		L5K: L5K_E0: pmr735_d_l5: vreg-pmr735-d-l5 {
			regulator-name = "pmr735_d_l5";
			qcom,set = <RPMH_REGULATOR_SET_ALL>;
			regulator-min-microvolt = <920000>;
			regulator-max-microvolt = <969000>;
			qcom,init-voltage = <920000>;
			qcom,init-mode = <RPMH_REGULATOR_MODE_HPM>;
		};
	};

	rpmh-regulator-l6k-e0 {
		compatible = "qcom,rpmh-vrm-regulator";
		qcom,resource-name = "L6K_E0";
		qcom,regulator-type = "pmic5-ldo";
		qcom,supported-modes =
			<RPMH_REGULATOR_MODE_LPM
			 RPMH_REGULATOR_MODE_HPM>;
		qcom,mode-threshold-currents = <0 30000>;

		L6K: L6K_E0: pmr735_d_l6: vreg-pmr735-d-l6 {
			regulator-name = "pmr735_d_l6";
			qcom,set = <RPMH_REGULATOR_SET_ALL>;
			regulator-min-microvolt = <1050000>;
			regulator-max-microvolt = <2000000>;
			qcom,init-voltage = <1050000>;
			qcom,init-mode = <RPMH_REGULATOR_MODE_HPM>;
		};
	};

	rpmh-regulator-l7k-e0 {
		compatible = "qcom,rpmh-vrm-regulator";
		qcom,resource-name = "L7K_E0";
		qcom,regulator-type = "pmic5-ldo";
		qcom,supported-modes =
			<RPMH_REGULATOR_MODE_LPM
			 RPMH_REGULATOR_MODE_HPM>;
		qcom,mode-threshold-currents = <0 30000>;

		L7K: L7K_E0: pmr735_d_l7: vreg-pmr735-d-l7 {
			regulator-name = "pmr735_d_l7";
			qcom,set = <RPMH_REGULATOR_SET_ALL>;
			regulator-min-microvolt = <556000>;
			regulator-max-microvolt = <816000>;
			qcom,init-voltage = <556000>;
			qcom,init-mode = <RPMH_REGULATOR_MODE_HPM>;
		};
	};

	rpmh-regulator-s1d-e0 {
		compatible = "qcom,rpmh-vrm-regulator";
		qcom,resource-name = "S1D_E0";

		S1D: S1D_E0:
		pm8550ve_d_s1: vreg-pm8550ve-d-s1 {
			regulator-name = "pm8550ve_d_s1";
			qcom,set = <RPMH_REGULATOR_SET_ALL>;
			regulator-min-microvolt = <352000>;
			regulator-max-microvolt = <916000>;
			qcom,init-voltage = <828000>;
		};
	};

	rpmh-regulator-s2d-e0 {
		compatible = "qcom,rpmh-vrm-regulator";
		qcom,resource-name = "S2D_E0";

		S2D: S2D_E0:
		pm8550ve_d_s2: vreg-pm8550ve-d-s2 {
			regulator-name = "pm8550ve_d_s3";
			qcom,set = <RPMH_REGULATOR_SET_ALL>;
			regulator-min-microvolt = <864000>;
			regulator-max-microvolt = <1100000>;
			qcom,init-voltage = <976000>;
		};
	};

	rpmh-regulator-s3d-e0 {
		compatible = "qcom,rpmh-vrm-regulator";
		qcom,resource-name = "S3D_E0";

		S3D: S3D_E0:
		pm8550ve_d_s3: vreg-pm8550ve-d-s3 {
			regulator-name = "pm8550ve_d_s3";
			qcom,set = <RPMH_REGULATOR_SET_ALL>;
			regulator-min-microvolt = <2156000>;
			regulator-max-microvolt = <2700000>;
			qcom,init-voltage = <2156000>;
		};
	};

	rpmh-regulator-s4d-e0 {
		compatible = "qcom,rpmh-vrm-regulator";
		qcom,resource-name = "S4D_E0";

		S4D: S4D_E0:
		pm8550ve_d_s4: vreg-pm8550ve-d-s4 {
			regulator-name = "pm8550ve_d_s4";
			qcom,set = <RPMH_REGULATOR_SET_ALL>;
			regulator-min-microvolt = <1840000>;
			regulator-max-microvolt = <2100000>;
			qcom,init-voltage = <1856000>;
		};
	};

	rpmh-regulator-l1d-e0 {
		compatible = "qcom,rpmh-vrm-regulator";
		qcom,resource-name = "L1D_E0";
		qcom,regulator-type = "pmic5-ldo";
		qcom,supported-modes =
			<RPMH_REGULATOR_MODE_LPM
			 RPMH_REGULATOR_MODE_HPM>;
		qcom,mode-threshold-currents = <0 30000>;

		L1D: L1D_E0:
		pm8550ve_d_l1: vreg-pm8550ve-d-l1 {
			regulator-name = "pm8550ve_d_l1";
			qcom,set = <RPMH_REGULATOR_SET_ALL>;
			regulator-min-microvolt = <752000>;
			regulator-max-microvolt = <824000>;
			qcom,init-voltage = <752000>;
			qcom,init-mode = <RPMH_REGULATOR_MODE_HPM>;
		};
	};

	rpmh-regulator-l2d-e0 {
		compatible = "qcom,rpmh-vrm-regulator";
		qcom,resource-name = "L2D_E0";
		qcom,regulator-type = "pmic5-ldo";
		qcom,supported-modes =
			<RPMH_REGULATOR_MODE_LPM
			 RPMH_REGULATOR_MODE_HPM>;
		qcom,mode-threshold-currents = <0 30000>;

		L2D: L2D_E0:
		pm8550ve_d_l2: vreg-pm8550ve-d-l2 {
			regulator-name = "pm8550ve_d_l2";
			qcom,set = <RPMH_REGULATOR_SET_ALL>;
			regulator-min-microvolt = <1620000>;
			regulator-max-microvolt = <2000000>;
			qcom,init-voltage = <1800000>;
			qcom,init-mode = <RPMH_REGULATOR_MODE_HPM>;
		};
	};

	rpmh-regulator-l3d-e0 {
		compatible = "qcom,rpmh-vrm-regulator";
		qcom,resource-name = "L3D_E0";
		qcom,regulator-type = "pmic5-ldo";
		qcom,supported-modes =
			<RPMH_REGULATOR_MODE_LPM
			 RPMH_REGULATOR_MODE_HPM>;
		qcom,mode-threshold-currents = <0 30000>;

		L3D: L3D_E0:
		pm8550ve_d_l3: vreg-pm8550ve-d-l3 {
			regulator-name = "pm8550ve_d_l3";
			qcom,set = <RPMH_REGULATOR_SET_ALL>;
			regulator-min-microvolt = <1080000>;
			regulator-max-microvolt = <1980000>;
			qcom,init-voltage = <1200000>;
			qcom,init-mode = <RPMH_REGULATOR_MODE_HPM>;
		};
	};

	rpmh-regulator-l1f-e0 {
		compatible = "qcom,rpmh-vrm-regulator";
		qcom,resource-name = "L1F_E0";
		qcom,regulator-type = "pmic5-ldo";
		qcom,supported-modes =
			<RPMH_REGULATOR_MODE_LPM
			 RPMH_REGULATOR_MODE_HPM>;
		qcom,mode-threshold-currents = <0 30000>;

		L1F: L1F_E0:
		pm8550ve_f_l1: vreg-pm8550ve-f-l1 {
			regulator-name = "pm8550ve_f_l1";
			qcom,set = <RPMH_REGULATOR_SET_ALL>;
			regulator-min-microvolt = <1000000>;
			regulator-max-microvolt = <1980000>;
			qcom,init-voltage = <1200000>;
			qcom,init-mode = <RPMH_REGULATOR_MODE_HPM>;
		};
	};

	rpmh-regulator-l2f-e0 {
		compatible = "qcom,rpmh-vrm-regulator";
		qcom,resource-name = "L2F_E0";
		qcom,regulator-type = "pmic5-ldo";
		qcom,supported-modes =
			<RPMH_REGULATOR_MODE_LPM
			 RPMH_REGULATOR_MODE_HPM>;
		qcom,mode-threshold-currents = <0 30000>;
		proxy-supply = <&L2F>;

		L2F: L2F_E0:
		pm8550ve_f_l2: vreg-pm8550ve-f-l2 {
			regulator-name = "pm8550ve_f_l2";
			qcom,set = <RPMH_REGULATOR_SET_ALL>;
			regulator-min-microvolt = <1080000>;
			regulator-max-microvolt = <1320000>;
			qcom,init-voltage = <1200000>;
			qcom,init-mode = <RPMH_REGULATOR_MODE_HPM>;
			qcom,proxy-consumer-enable;
			qcom,proxy-consumer-current = <16600>;
		};
	};

	rpmh-regulator-l3f-e0 {
		compatible = "qcom,rpmh-vrm-regulator";
		qcom,resource-name = "L3F_E0";
		qcom,regulator-type = "pmic5-ldo";
		qcom,supported-modes =
			<RPMH_REGULATOR_MODE_LPM
			 RPMH_REGULATOR_MODE_HPM>;
		qcom,mode-threshold-currents = <0 30000>;
		proxy-supply = <&L3F>;

		L3F: L3F_E0:
		pm8550ve_f_l3: vreg-pm8550ve-f-l3 {
			regulator-name = "pm8550ve_f_l3";
			qcom,set = <RPMH_REGULATOR_SET_ALL>;
			regulator-min-microvolt = <1200000>;
			regulator-max-microvolt = <1200000>;
			qcom,proxy-consumer-enable;
			qcom,proxy-consumer-current = <31000>;
			qcom,init-voltage = <1200000>;
			qcom,init-mode = <RPMH_REGULATOR_MODE_HPM>;
		};
	};

	rpmh-regulator-s4f-e0 {
		compatible = "qcom,rpmh-vrm-regulator";
		qcom,resource-name = "S4F_E0";
		qcom,regulator-type = "pmic5-ftsmps";
		qcom,supported-modes = <RPMH_REGULATOR_MODE_RET
					RPMH_REGULATOR_MODE_HPM>;
		qcom,mode-threshold-currents = <0 50000>;

		S4F: S4F_E0:
		pm8550ve_f_s4: vreg-pm8550ve-f-s4 {
			regulator-name = "pm8550ve_f_s4";
			qcom,set = <RPMH_REGULATOR_SET_ALL>;
			regulator-min-microvolt = <1240000>;
			regulator-max-microvolt = <1400000>;
			qcom,init-voltage = <1304000>;
			qcom,init-mode = <RPMH_REGULATOR_MODE_RET>;
		};
	};

	VRM_S5F: rpmh-regulator-s5f-e0 {
		compatible = "qcom,rpmh-vrm-regulator";
		qcom,resource-name = "S5F_E0";

		S5F: S5F_E0:
		pm8550ve_f_s5: vreg-pm8550ve-f-s5 {
			regulator-name = "pm8550ve_f_s5";
			qcom,set = <RPMH_REGULATOR_SET_ALL>;
			regulator-min-microvolt = <1010000>;
			regulator-max-microvolt = <1120000>;
			qcom,init-voltage = <1052000>;
		};
	};

	rpmh-regulator-s3g-e0 {
		compatible = "qcom,rpmh-vrm-regulator";
		qcom,resource-name = "S3G_E0";

		S3G: S3G_E0:
		pm8550ve_g_s3: vreg-pm8550ve-g-s3 {
			regulator-name = "pm8550ve_g_s3";
			qcom,set = <RPMH_REGULATOR_SET_ALL>;
			regulator-min-microvolt = <300000>;
			regulator-max-microvolt = <570000>;
			qcom,init-voltage = <504000>;
		};
	};

	rpmh-regulator-s4g-e0 {
		compatible = "qcom,rpmh-vrm-regulator";
		qcom,resource-name = "S4G_E0";

		S4G: S4G_E0:
		pm8550ve_g_s4: vreg-pm8550ve-g-s4 {
			regulator-name = "pm8550ve_g_s4";
			qcom,set = <RPMH_REGULATOR_SET_ALL>;
			regulator-min-microvolt = <870000>;
			regulator-max-microvolt = <970000>;
			qcom,init-voltage = <904000>;
		};
	};

	rpmh-regulator-l2g-e0 {
		compatible = "qcom,rpmh-vrm-regulator";
		qcom,resource-name = "L2G_E0";
		qcom,regulator-type = "pmic5-ldo";
		qcom,supported-modes =
			<RPMH_REGULATOR_MODE_LPM
			 RPMH_REGULATOR_MODE_HPM>;
		qcom,mode-threshold-currents = <0 30000>;

		L2G: L2G_E0:
		pm8550ve_g_l2: vreg-pm8550ve-g-l2 {
			regulator-name = "pm8550ve_g_l2";
			qcom,set = <RPMH_REGULATOR_SET_ALL>;
			regulator-min-microvolt = <866000>;
			regulator-max-microvolt = <958000>;
			qcom,init-voltage = <866000>;
			qcom,init-mode = <RPMH_REGULATOR_MODE_HPM>;
		};
	};

	rpmh-regulator-l1i-e0 {
		compatible = "qcom,rpmh-vrm-regulator";
		qcom,resource-name = "L1I_E0";
		qcom,regulator-type = "pmic5-ldo";
		qcom,supported-modes =
			<RPMH_REGULATOR_MODE_LPM
			 RPMH_REGULATOR_MODE_HPM>;
		qcom,mode-threshold-currents = <0 30000>;

		L1I: L1I_E0:
		pm8550ve_i_l1: vreg-pm8550ve-i-l1 {
			regulator-name = "pm8550ve_i_l1";
			qcom,set = <RPMH_REGULATOR_SET_ALL>;
			regulator-min-microvolt = <866000>;
			regulator-max-microvolt = <958000>;
			qcom,init-voltage = <912000>;
			qcom,init-mode = <RPMH_REGULATOR_MODE_HPM>;
		};
	};

	rpmh-regulator-l2i-e0 {
		compatible = "qcom,rpmh-vrm-regulator";
		qcom,resource-name = "L2I_E0";
		qcom,regulator-type = "pmic5-ldo";
		qcom,supported-modes =
			<RPMH_REGULATOR_MODE_RET
			 RPMH_REGULATOR_MODE_HPM>;
		qcom,mode-threshold-currents = <0 30000>;
		proxy-supply = <&L2I>;

		L2I: L2I_E0:
		pm8550ve_i_l2: vreg-pm8550ve-i-l2 {
			regulator-name = "pm8550ve_i_l2";
			qcom,set = <RPMH_REGULATOR_SET_ALL>;
			regulator-min-microvolt = <720000>;
			regulator-max-microvolt = <950000>;
			qcom,init-voltage = <880000>;
			qcom,init-mode = <RPMH_REGULATOR_MODE_HPM>;
			qcom,proxy-consumer-enable;
			qcom,proxy-consumer-current = <98000>;
		};
	};

	rpmh-regulator-l3i-e0 {
		compatible = "qcom,rpmh-vrm-regulator";
		qcom,resource-name = "L3I_E0";
		qcom,regulator-type = "pmic5-ldo";
		qcom,supported-modes =
			<RPMH_REGULATOR_MODE_LPM
			 RPMH_REGULATOR_MODE_HPM>;
		qcom,mode-threshold-currents = <0 30000>;

		L3I: L3I_E0:
		pm550ve_i_l3: vreg-pm8550ve-i-l3 {
			regulator-name = "pm8550ve_i_l3";
			qcom,set = <RPMH_REGULATOR_SET_ALL>;
			regulator-min-microvolt = <720000>;
			regulator-max-microvolt = <950000>;
			qcom,init-voltage = <880000>;
			qcom,init-mode = <RPMH_REGULATOR_MODE_HPM>;
		};
	};
};
